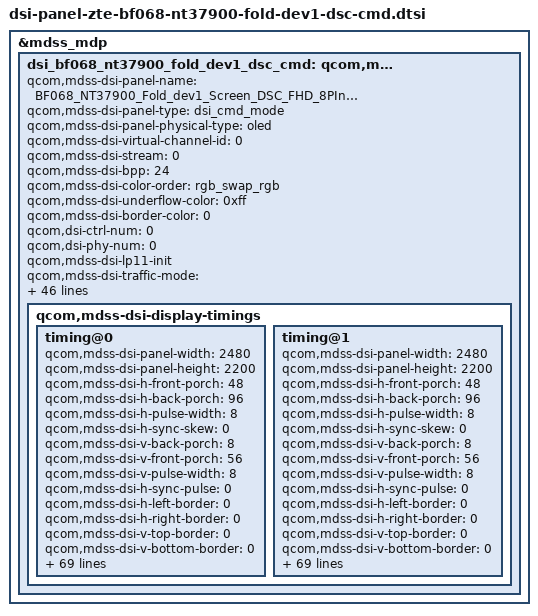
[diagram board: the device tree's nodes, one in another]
&mdss_mdp {
	dsi_bf068_nt37900_fold_dev1_dsc_cmd: qcom,mdss_dsi_bf068_nt37900_fold_dev1_dsc_cmd {
		qcom,mdss-dsi-panel-name =
				"BF068_NT37900_Fold_dev1_Screen_DSC_FHD_8PInch";
		qcom,mdss-dsi-panel-type = "dsi_cmd_mode";
		qcom,mdss-dsi-panel-physical-type = "oled";
		qcom,mdss-dsi-virtual-channel-id = <0>;
		qcom,mdss-dsi-stream = <0>;
		qcom,mdss-dsi-bpp = <24>;
		qcom,mdss-dsi-color-order = "rgb_swap_rgb";
		qcom,mdss-dsi-underflow-color = <0xff>;
		qcom,mdss-dsi-border-color = <0>;

		qcom,dsi-ctrl-num = <0>;
		qcom,dsi-phy-num = <0>;
		qcom,mdss-dsi-lp11-init;
		qcom,mdss-dsi-traffic-mode = "non_burst_sync_event";
		qcom,mdss-dsi-bllp-eof-power-mode;
		qcom,mdss-dsi-bllp-power-mode;
		qcom,mdss-dsi-lane-0-state;
		qcom,mdss-dsi-lane-1-state;
		qcom,mdss-dsi-lane-2-state;
		qcom,mdss-dsi-dma-trigger = "trigger_sw";
		qcom,mdss-dsi-mdp-trigger = "none";
		qcom,mdss-dsi-reset-sequence = <1 5>, <0 5>, <1 10>;
		qcom,mdss-dsi-tx-eot-append;

		qcom,mdss-dsi-te-pin-select = <1>;
		qcom,mdss-dsi-te-dcs-command = <1>;
		qcom,mdss-dsi-te-check-enable;
		qcom,mdss-dsi-te-using-te-pin;
		qcom,panel-cphy-mode;
		qcom,mdss-dsi-bl-min-level = <80>;
		qcom,mdss-dsi-bl-max-level = <3515>;
		qcom,mdss-dsi-panel-hdr-enabled;
		qcom,mdss-dsi-panel-hdr-color-primaries = <14500 15500 34015
			15980 13030 34670 6950 2565>;
		qcom,mdss-dsi-panel-peak-brightness = <6680000>;
		qcom,mdss-dsi-panel-blackness-level = <20>;
		qcom,mdss-pan-physical-width-dimension = <148>;
		qcom,mdss-pan-physical-height-dimension = <132>;
		qcom,bl-dcs-cmd-state = "dsi_lp_mode";
		qcom,mdss-dsi-display-timings {
			timing@0{
				qcom,mdss-dsi-panel-width = <2480>;
				qcom,mdss-dsi-panel-height = <2200>;
				qcom,mdss-dsi-h-front-porch = <48>;
				qcom,mdss-dsi-h-back-porch = <96>;
				qcom,mdss-dsi-h-pulse-width = <8>;
				qcom,mdss-dsi-h-sync-skew = <0>;
				qcom,mdss-dsi-v-back-porch = <8>;
				qcom,mdss-dsi-v-front-porch = <56>;
				qcom,mdss-dsi-v-pulse-width = <8>;
				qcom,mdss-dsi-h-sync-pulse = <0>;
				qcom,mdss-dsi-h-left-border = <0>;
				qcom,mdss-dsi-h-right-border = <0>;
				qcom,mdss-dsi-v-top-border = <0>;
				qcom,mdss-dsi-v-bottom-border = <0>;
				qcom,mdss-dsi-panel-framerate = <60>;
				//qcom,mdss-dsi-panel-clockrate = <466980000>;
				qcom,mdss-mdp-transfer-time-us = <6235>;

				qcom,mdss-dsi-on-command = [
					//===============ACL START============
					39 01 00 00 00 00 06 F0 55 AA 52 08 00
					39 01 00 00 00 00 02 B0 0C
					39 01 00 00 00 00 02 6F 09
					39 01 00 00 00 00 04 B0 55 56 55
					39 01 00 00 00 00 04 B1 17 3B 5C
					39 01 00 00 00 00 02 6F 03
					39 01 00 00 00 00 03 B1 00 17
					39 01 00 00 00 00 02 6F 14
					39 01 00 00 00 00 03 B1 00 3B
					39 01 00 00 00 00 02 6F 16
					39 01 00 00 00 00 03 B1 00 5C
					39 01 00 00 00 00 02 6F 05
					39 01 00 00 00 00 0D B1 12 34 57 89 2C 58 84 B0 DC 08 34 60
					39 01 00 00 00 00 02 6F 21
					39 01 00 00 00 00 0F B1 00 00 24 68 AC EF 00 00 00 00 00 00 00 FF
					39 01 00 00 00 00 02 6F 18
					39 01 00 00 00 00 07 B1 04 D8 09 B0 04 D8
					39 01 00 00 00 00 02 6F 1E
					39 01 00 00 00 00 04 B1 14 D0 20
					//===============ACL END============

					39 01 00 00 00 00 06 F0 55 AA 52 08 00
					39 01 00 00 00 00 02 6F 1B
					39 01 00 00 00 00 02 BA 08
					39 01 00 00 00 00 02 6F 1C
					39 01 00 00 00 00 11 BA 01 01 01 01 00 00 01 01 00 00 01 01 00 00 00 00
					39 01 00 00 00 00 02 6F 2C
					39 01 00 00 00 00 11 BA 00 01 00 01 00 01 00 02 00 01 00 02 00 00 00 00
					39 01 00 00 00 00 02 6F 3C
					39 01 00 00 00 00 11 BA 00 01 00 01 00 02 00 05 00 02 00 05 00 00 00 00
					39 01 00 00 00 00 02 6F 4C
					39 01 00 00 00 00 11 BA 00 01 00 00 00 05 00 00 00 05 00 00 00 00 00 00
					39 01 00 00 00 00 02 6F 5C
					39 01 00 00 00 00 11 BA 01 01 01 01 01 01 01 01 01 01 01 01 01 01 01 01
					39 01 00 00 00 00 02 6F 6C
					39 01 00 00 00 00 11 BA 00 77 01 77 77 00 00 00 00 00 00 00 00 00 00 00
					39 01 00 00 00 00 02 6F 7C
					39 01 00 00 00 00 11 BA 00 77 01 77 77 00 00 00 00 00 00 00 00 00 00 00
					39 01 00 00 00 00 02 6F 8C
					39 01 00 00 00 00 11 BA 00 00 00 00 00 00 00 00 00 00 00 00 00 00 00 00
					39 01 00 00 00 00 02 6F 9C
					39 01 00 00 00 00 09 BA 11 11 10 10 10 10 10 00
					39 01 00 00 00 00 02 6F A4
					39 01 00 00 00 00 05 BA E4 02 00 00
					39 01 00 00 00 00 02 6F A8
					39 01 00 00 00 00 09 BA 00 00 00 10 11 11 11 11
					39 01 00 00 00 00 02 6F B0
					39 01 00 00 00 00 09 BA 00 00 00 10 11 11 11 11
					39 01 00 00 00 00 02 5A 00
					39 01 00 00 00 00 06 F0 55 AA 52 08 01
					39 01 00 00 00 00 02 6F 31
					39 01 00 00 00 00 06 B9 4A 4A 4A 4A 4A
					39 01 00 00 00 00 02 6F 36
					39 01 00 00 00 00 07 C6 1E 1E 1E 1E 1E 1E
					39 01 00 00 00 00 02 6F 36
					39 01 00 00 00 00 02 B9 1E
					39 01 00 00 00 00 02 6F 37
					39 01 00 00 00 00 06 B9 1E 1E 1E 1E 1E
					39 01 00 00 00 00 02 6F 3C
					39 01 00 00 00 00 06 B9 1D 1D 1D 1D 1D
					39 01 00 00 00 00 05 FF AA 55 A5 80
					39 01 00 00 00 00 02 6F 29
					39 01 00 00 00 00 03 F8 01 6F
					39 01 00 00 00 00 02 6F 0D
					39 01 00 00 00 00 03 F8 01 7F
					39 01 00 00 00 00 02 6F 02
					39 01 00 00 00 00 02 F7 60
					39 01 00 00 00 00 05 FF AA 55 A5 81
					39 01 00 00 00 00 02 6F 04
					39 01 00 00 00 00 03 FE 3C 3C
					39 01 00 00 00 00 02 6F 0F
					39 01 00 00 00 00 02 F5 20
					39 01 00 00 00 00 02 6F 02
					39 01 00 00 00 00 02 F9 00
					39 01 00 00 00 00 05 FF AA 55 A5 82
					39 01 00 00 00 00 02 6F 09
					39 01 00 00 00 00 02 F2 DE
					39 01 00 00 00 00 02 6F 08
					39 01 00 00 00 00 03 F3 EE 0E
					39 01 00 00 00 00 06 F0 55 AA 52 00 00
					39 01 00 00 00 00 05 FF AA 55 A5 00
					39 01 00 00 00 00 05 35 00 00 00 01
					39 01 00 00 00 00 02 53 20
					39 01 00 00 00 00 05 2A 00 00 09 AF
					39 01 00 00 00 00 05 2B 00 00 08 97
					39 01 00 00 00 00 02 26 00
					39 01 00 00 00 00 03 51 0D BB
					39 01 00 00 00 00 02 6F 04
					39 01 00 00 00 00 03 51 0F FE
					39 01 00 00 00 00 03 81 01 19
					39 01 00 00 00 00 02 90 03
					39 01 00 00 00 00 13 91 89 28 00 32 C2 00 03 6D 06 C6 00 11 01 F6 00 E0 10 D0
					05 01 00 00 00 00 01 2C
					39 01 00 00 00 00 02 2F 30
					39 01 00 00 00 00 02 6D 03
					05 01 00 00 78 00 01 11
					05 01 00 00 00 00 01 29
					];
				qcom,mdss-dsi-off-command = [
					05 01 00 00 14 00 01 28
					05 01 00 00 78 00 01 10
				];
				qcom,mdss-dsi-on-command-state = "dsi_lp_mode";
				qcom,mdss-dsi-off-command-state = "dsi_lp_mode";

				qcom,mdss-dsi-lp1-command = [
					05 01 00 00 00 00 01 39
					05 01 00 00 00 00 01 2C
				];
				qcom,mdss-dsi-lp1-command-state =
					"dsi_lp_mode";
				qcom,mdss-dsi-nolp-command = [
					39 01 00 00 00 00 03 51 00 00
					05 01 00 00 00 00 01 38
					05 01 00 00 00 00 01 2C
				];
				qcom,mdss-dsi-nolp-command-state =
					"dsi_lp_mode";
				qcom,mdss-dsi-timing-switch-command = [
					39 01 00 00 00 00 05 35 00 00 00 01
					39 01 00 00 00 00 02 2F 30
					39 01 00 00 00 00 02 6D 03
				];
				qcom,mdss-dsi-timing-switch-command-state =
				    "dsi_lp_mode";
				qcom,compression-mode = "dsc";
				qcom,mdss-dsc-slice-height = <50>;
				qcom,mdss-dsc-slice-width = <1240>;
				qcom,mdss-dsc-slice-per-pkt = <2>;
				qcom,mdss-dsc-bit-per-component = <8>;
				qcom,mdss-dsc-bit-per-pixel = <8>;
				qcom,mdss-dsc-block-prediction-enable;
			};
			timing@1{
				qcom,mdss-dsi-panel-width = <2480>;
				qcom,mdss-dsi-panel-height = <2200>;
				qcom,mdss-dsi-h-front-porch = <48>;
				qcom,mdss-dsi-h-back-porch = <96>;
				qcom,mdss-dsi-h-pulse-width = <8>;
				qcom,mdss-dsi-h-sync-skew = <0>;
				qcom,mdss-dsi-v-back-porch = <8>;
				qcom,mdss-dsi-v-front-porch = <56>;
				qcom,mdss-dsi-v-pulse-width = <8>;
				qcom,mdss-dsi-h-sync-pulse = <0>;
				qcom,mdss-dsi-h-left-border = <0>;
				qcom,mdss-dsi-h-right-border = <0>;
				qcom,mdss-dsi-v-top-border = <0>;
				qcom,mdss-dsi-v-bottom-border = <0>;
				qcom,mdss-dsi-panel-framerate = <120>;
				//qcom,mdss-dsi-panel-clockrate = <894120000>;
				qcom,mdss-mdp-transfer-time-us = <6235>;

				qcom,mdss-dsi-on-command = [
					//===============ACL START============
					39 01 00 00 00 00 06 F0 55 AA 52 08 00
					39 01 00 00 00 00 02 B0 0C
					39 01 00 00 00 00 02 6F 09
					39 01 00 00 00 00 04 B0 55 56 55
					39 01 00 00 00 00 04 B1 17 3B 5C
					39 01 00 00 00 00 02 6F 03
					39 01 00 00 00 00 03 B1 00 17
					39 01 00 00 00 00 02 6F 14
					39 01 00 00 00 00 03 B1 00 3B
					39 01 00 00 00 00 02 6F 16
					39 01 00 00 00 00 03 B1 00 5C
					39 01 00 00 00 00 02 6F 05
					39 01 00 00 00 00 0D B1 12 34 57 89 2C 58 84 B0 DC 08 34 60
					39 01 00 00 00 00 02 6F 21
					39 01 00 00 00 00 0F B1 00 00 24 68 AC EF 00 00 00 00 00 00 00 FF
					39 01 00 00 00 00 02 6F 18
					39 01 00 00 00 00 07 B1 04 D8 09 B0 04 D8
					39 01 00 00 00 00 02 6F 1E
					39 01 00 00 00 00 04 B1 14 D0 20
					//===============ACL END============

					39 01 00 00 00 00 06 F0 55 AA 52 08 00
					39 01 00 00 00 00 02 6F 1B
					39 01 00 00 00 00 02 BA 08
					39 01 00 00 00 00 02 6F 1C
					39 01 00 00 00 00 11 BA 01 01 01 01 00 00 01 01 00 00 01 01 00 00 00 00
					39 01 00 00 00 00 02 6F 2C
					39 01 00 00 00 00 11 BA 00 01 00 01 00 01 00 02 00 01 00 02 00 00 00 00
					39 01 00 00 00 00 02 6F 3C
					39 01 00 00 00 00 11 BA 00 01 00 01 00 02 00 05 00 02 00 05 00 00 00 00
					39 01 00 00 00 00 02 6F 4C
					39 01 00 00 00 00 11 BA 00 01 00 00 00 05 00 00 00 05 00 00 00 00 00 00
					39 01 00 00 00 00 02 6F 5C
					39 01 00 00 00 00 11 BA 01 01 01 01 01 01 01 01 01 01 01 01 01 01 01 01
					39 01 00 00 00 00 02 6F 6C
					39 01 00 00 00 00 11 BA 00 77 01 77 77 00 00 00 00 00 00 00 00 00 00 00
					39 01 00 00 00 00 02 6F 7C
					39 01 00 00 00 00 11 BA 00 77 01 77 77 00 00 00 00 00 00 00 00 00 00 00
					39 01 00 00 00 00 02 6F 8C
					39 01 00 00 00 00 11 BA 00 00 00 00 00 00 00 00 00 00 00 00 00 00 00 00
					39 01 00 00 00 00 02 6F 9C
					39 01 00 00 00 00 09 BA 11 11 10 10 10 10 10 00
					39 01 00 00 00 00 02 6F A4
					39 01 00 00 00 00 05 BA E4 02 00 00
					39 01 00 00 00 00 02 6F A8
					39 01 00 00 00 00 09 BA 00 00 00 10 11 11 11 11
					39 01 00 00 00 00 02 6F B0
					39 01 00 00 00 00 09 BA 00 00 00 10 11 11 11 11
					39 01 00 00 00 00 02 5A 00
					39 01 00 00 00 00 06 F0 55 AA 52 08 01
					39 01 00 00 00 00 02 6F 31
					39 01 00 00 00 00 06 B9 4A 4A 4A 4A 4A
					39 01 00 00 00 00 02 6F 36
					39 01 00 00 00 00 07 C6 1E 1E 1E 1E 1E 1E
					39 01 00 00 00 00 02 6F 36
					39 01 00 00 00 00 02 B9 1E
					39 01 00 00 00 00 02 6F 37
					39 01 00 00 00 00 06 B9 1E 1E 1E 1E 1E
					39 01 00 00 00 00 02 6F 3C
					39 01 00 00 00 00 06 B9 1D 1D 1D 1D 1D
					39 01 00 00 00 00 05 FF AA 55 A5 80
					39 01 00 00 00 00 02 6F 29
					39 01 00 00 00 00 03 F8 01 6F
					39 01 00 00 00 00 02 6F 0D
					39 01 00 00 00 00 03 F8 01 7F
					39 01 00 00 00 00 02 6F 02
					39 01 00 00 00 00 02 F7 60
					39 01 00 00 00 00 05 FF AA 55 A5 81
					39 01 00 00 00 00 02 6F 04
					39 01 00 00 00 00 03 FE 3C 3C
					39 01 00 00 00 00 02 6F 0F
					39 01 00 00 00 00 02 F5 20
					39 01 00 00 00 00 02 6F 02
					39 01 00 00 00 00 02 F9 00
					39 01 00 00 00 00 05 FF AA 55 A5 82
					39 01 00 00 00 00 02 6F 09
					39 01 00 00 00 00 02 F2 DE
					39 01 00 00 00 00 02 6F 08
					39 01 00 00 00 00 03 F3 EE 0E
					39 01 00 00 00 00 06 F0 55 AA 52 00 00
					39 01 00 00 00 00 05 FF AA 55 A5 00
					39 01 00 00 00 00 05 35 00 00 00 00
					39 01 00 00 00 00 02 53 20
					39 01 00 00 00 00 05 2A 00 00 09 AF
					39 01 00 00 00 00 05 2B 00 00 08 97
					39 01 00 00 00 00 02 26 00
					39 01 00 00 00 00 03 51 0D BB
					39 01 00 00 00 00 02 6F 04
					39 01 00 00 00 00 03 51 0F FE
					39 01 00 00 00 00 03 81 01 19
					39 01 00 00 00 00 02 90 03
					39 01 00 00 00 00 13 91 89 28 00 32 C2 00 03 6D 06 C6 00 11 01 F6 00 E0 10 D0
					05 01 00 00 00 00 01 2C
					39 01 00 00 00 00 02 2F 30
					39 01 00 00 00 00 02 6D 01
					05 01 00 00 78 00 01 11
					05 01 00 00 00 00 01 29
					];
				qcom,mdss-dsi-off-command = [
					05 01 00 00 14 00 01 28
					05 01 00 00 78 00 01 10
				];
				qcom,mdss-dsi-on-command-state = "dsi_lp_mode";
				qcom,mdss-dsi-off-command-state = "dsi_lp_mode";

				qcom,mdss-dsi-lp1-command = [
					05 01 00 00 00 00 01 39
					05 01 00 00 00 00 01 2C
				];
				qcom,mdss-dsi-lp1-command-state =
					"dsi_lp_mode";
				qcom,mdss-dsi-nolp-command = [
					05 01 00 00 00 00 01 38
					05 01 00 00 00 00 01 2C
				];
				qcom,mdss-dsi-nolp-command-state =
					"dsi_lp_mode";
				qcom,mdss-dsi-timing-switch-command = [
					39 01 00 00 00 00 05 35 00 00 00 00
					39 01 00 00 00 00 02 2F 30
					39 01 00 00 00 00 02 6D 01
				];
				qcom,mdss-dsi-timing-switch-command-state =
				    "dsi_lp_mode";
				qcom,compression-mode = "dsc";
				qcom,mdss-dsc-slice-height = <50>;
				qcom,mdss-dsc-slice-width = <1240>;
				qcom,mdss-dsc-slice-per-pkt = <2>;
				qcom,mdss-dsc-bit-per-component = <8>;
				qcom,mdss-dsc-bit-per-pixel = <8>;
				qcom,mdss-dsc-block-prediction-enable;
			};
		};
	};
};

/* panel feature */
&dsi_bf068_nt37900_fold_dev1_dsc_cmd {
	/* zte disp feature */
	zte,hbm_enabled;
	zte,hdr_enabled;
	zte,hdr_threshold = <0xE80>;
	zte,fps_enabled;
	zte,acl_enabled;
	zte,aod_enabled;
	zte,color_space_enabled;
	zte,hdr_brightness = <0xFFF>;
	zte,aod-exit-delay-time = <150>;
	zte,second_irq_fps_enabled;
	zte,lcd-fps-irq-gpio = <&tlmm 87 0>;
	qcom,mdss-dsi-display-timings {
		timing@0 {
			zte,mdss-dsi-reg-read-commands = [
				06 01 00 00 00 00 01 A0
			];
			zte,mdss-dsi-aod-low-commands = [
				39 01 00 00 00 00 06 F0 55 AA 52 08 00
				39 01 00 00 00 00 02 6F B8
				39 01 00 00 00 00 0B B4 08 98 08 98 08 98 08 98 08 98
			];
			zte,mdss-dsi-aod-mid-commands = [
				39 01 00 00 00 00 06 F0 55 AA 52 08 00
				39 01 00 00 00 00 02 6F B8
				39 01 00 00 00 00 0B B4 07 80 07 80 07 80 07 80 07 80
			];
			zte,mdss-dsi-aod-high-commands = [
				39 01 00 00 00 00 06 F0 55 AA 52 08 00
				39 01 00 00 00 00 02 6F B8
				39 01 00 00 00 00 0B B4 04 80 04 80 04 80 04 80 04 80
			];
			zte,mdss-dsi-restore-bl-commands = [
				39 01 00 00 00 00 03 51 03 FF
			];
			zte,mdss-dsi-reg-read-commands = [
			    06 01 00 00 00 00 01 A0
			];
			zte,mdss-dsi-dim-on-commands = [
				15 01 00 00 00 00 02 53 28
			];
			zte,mdss-dsi-acl-off-commands = [
				15 01 00 00 00 00 02 55 00
			];
			zte,mdss-dsi-acl-low-commands = [
				15 01 00 00 00 00 02 55 04
			];
			zte,mdss-dsi-acl-mid-commands = [
				15 01 00 00 00 00 02 55 05
			];
			zte,mdss-dsi-acl-high-commands = [
				15 01 00 00 00 00 02 55 06
			];
			zte,mdss-dsi-reg-read-commands-state = "dsi_lp_mode";
			zte,mdss-dsi-aod-low-commands-state = "dsi_lp_mode";
			zte,mdss-dsi-aod-mid-commands-state = "dsi_lp_mode";
			zte,mdss-dsi-aod-high-commands-state = "dsi_lp_mode";
			zte,mdss-dsi-restore-bl-commands-state = "dsi_lp_mode";
			zte,mdss-dsi-dim-on-commands-state = "dsi_lp_mode";
			zte,mdss-dsi-acl-off-commands-state = "dsi_lp_mode";
			zte,mdss-dsi-acl-low-commands-state = "dsi_lp_mode";
			zte,mdss-dsi-acl-mid-commands-state = "dsi_lp_mode";
			zte,mdss-dsi-acl-high-commands-state = "dsi_lp_mode";
		};
		timing@1 {
			zte,mdss-dsi-reg-read-commands = [
				06 01 00 00 00 00 01 A0
			];
			zte,mdss-dsi-aod-low-commands = [
				39 01 00 00 00 00 06 F0 55 AA 52 08 00
				39 01 00 00 00 00 02 6F B8
				39 01 00 00 00 00 0B B4 08 98 08 98 08 98 08 98 08 98
			];
			zte,mdss-dsi-aod-mid-commands = [
				39 01 00 00 00 00 06 F0 55 AA 52 08 00
				39 01 00 00 00 00 02 6F B8
				39 01 00 00 00 00 0B B4 07 80 07 80 07 80 07 80 07 80
			];
			zte,mdss-dsi-aod-high-commands = [
				39 01 00 00 00 00 06 F0 55 AA 52 08 00
				39 01 00 00 00 00 02 6F B8
				39 01 00 00 00 00 0B B4 04 80 04 80 04 80 04 80 04 80
			];
			zte,mdss-dsi-restore-bl-commands = [
				39 01 00 00 00 00 03 51 03 FF
			];
			zte,mdss-dsi-reg-read-commands = [
			    06 01 00 00 00 00 01 A0
			];
			zte,mdss-dsi-dim-on-commands = [
				15 01 00 00 00 00 02 53 28
			];
			zte,mdss-dsi-acl-off-commands = [
				15 01 00 00 00 00 02 55 00
			];
			zte,mdss-dsi-acl-low-commands = [
				15 01 00 00 00 00 02 55 04
			];
			zte,mdss-dsi-acl-mid-commands = [
				15 01 00 00 00 00 02 55 05
			];
			zte,mdss-dsi-acl-high-commands = [
				15 01 00 00 00 00 02 55 06
			];
			zte,mdss-dsi-reg-read-commands-state = "dsi_lp_mode";
			zte,mdss-dsi-aod-low-commands-state = "dsi_lp_mode";
			zte,mdss-dsi-aod-mid-commands-state = "dsi_lp_mode";
			zte,mdss-dsi-aod-high-commands-state = "dsi_lp_mode";
			zte,mdss-dsi-restore-bl-commands-state = "dsi_lp_mode";
			zte,mdss-dsi-dim-on-commands-state = "dsi_lp_mode";
			zte,mdss-dsi-acl-off-commands-state = "dsi_lp_mode";
			zte,mdss-dsi-acl-low-commands-state = "dsi_lp_mode";
			zte,mdss-dsi-acl-mid-commands-state = "dsi_lp_mode";
			zte,mdss-dsi-acl-high-commands-state = "dsi_lp_mode";
		};
	};
};

/* zte dsip power supply */
&dsi_bf068_nt37900_fold_dev1_dsc_cmd {
	qcom,panel-supply-entries = <&dsi_panel_pwr_supply_a50u>;
	qcom,mdss-dsi-bl-pmic-control-type = "bl_ctrl_dcs";
	qcom,mdss-brightness-max-level = <2047>;
	qcom,mdss-dsi-bl-inverted-dbv;
	qcom,platform-reset-gpio = <&tlmm 133 0>;
	qcom,ulps-enabled;
	qcom,dsi-select-clocks = "pll_byte_clk0", "pll_dsi_clk0";
	qcom,mdss-dsi-display-timings {
		timing@0 {
			/* DPHY regular margins */
			//qcom,mdss-dsi-panel-phy-timings = [00 00 00 00 13 1A 05
			//		19 04 02 04 00 00 00];
			qcom,mdss-dsi-panel-phy-timings = [00 00 00 00 1A 27 09
					19 09 02 04 00 00 00];
			qcom,display-topology = <2 2 1>;
			qcom,default-topology-index = <0>;
		};
		timing@1 {
			/* DPHY regular margins */
			qcom,mdss-dsi-panel-phy-timings = [00 00 00 00 1A 27 09
					19 09 02 04 00 00 00];
			qcom,display-topology = <2 2 1>;
			qcom,default-topology-index = <0>;
		};
	};
};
